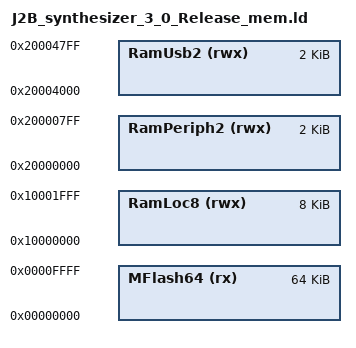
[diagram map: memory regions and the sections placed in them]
/*
 * GENERATED FILE - DO NOT EDIT
 * (c) Code Red Technologies Ltd, 2008-2015
 * (c) NXP Semiconductors 2013-2015
 * Linker script memory definitions
 * Created from LinkMemoryTemplate
 * By LPCXpresso v7.0.2 [Build 102] [2014-03-11]  on Wed May 06 22:53:42 CEST 2015)
*/

MEMORY
{
  /* Define each memory region */
  MFlash64 (rx) : ORIGIN = 0x0, LENGTH = 0x10000 /* 64K bytes */
  RamLoc8 (rwx) : ORIGIN = 0x10000000, LENGTH = 0x2000 /* 8K bytes */
  RamUsb2 (rwx) : ORIGIN = 0x20004000, LENGTH = 0x800 /* 2K bytes */
  RamPeriph2 (rwx) : ORIGIN = 0x20000000, LENGTH = 0x800 /* 2K bytes */


}
  /* Define a symbol for the top of each memory region */
  __top_MFlash64 = 0x0 + 0x10000;
  __top_RamLoc8 = 0x10000000 + 0x2000;
  __top_RamUsb2 = 0x20004000 + 0x800;
  __top_RamPeriph2 = 0x20000000 + 0x800;



